# STM32F412VGT7 register map
File version: 1.0
Registers are 32-bit, access not given, reset 0x0 unless marked. A register's access mark holds for its fields unless they carry their own. Offsets are from the block's base; [hi:lo] are bit positions; {n}, {i} and the like mark numbered series.

## GPIOA
Base 0x40020000
Same registers: GPIOB 0x40020400, GPIOC 0x40020800, GPIOD 0x40020C00, GPIOE 0x40021000, GPIOH 0x40021C00
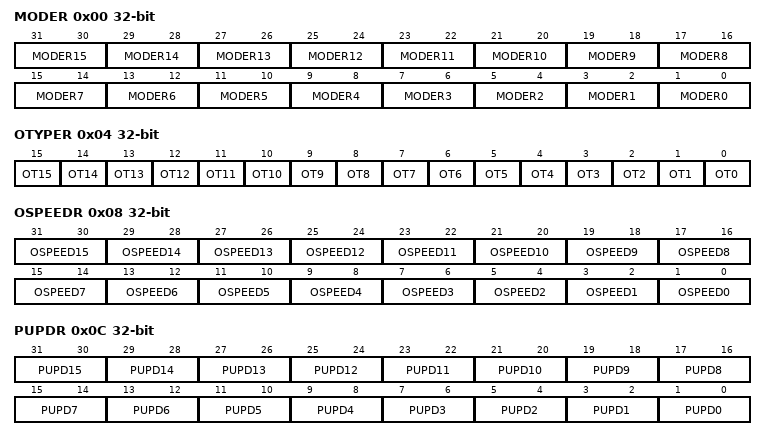
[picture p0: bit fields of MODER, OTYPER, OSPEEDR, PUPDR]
0x00 MODER
  [2n+1:2n] MODER{n} (n=0..15)
0x04 OTYPER
  [n] OT{n} (n=0..15)
0x08 OSPEEDR
  [2n+1:2n] OSPEED{n} (n=0..15)
0x0C PUPDR
  [2n+1:2n] PUPD{n} (n=0..15)
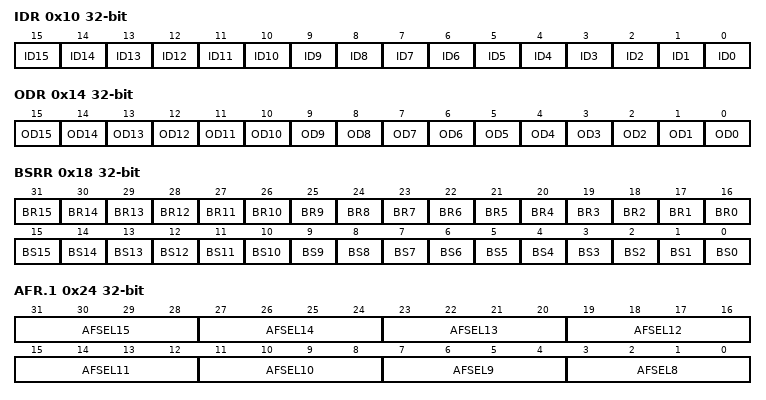
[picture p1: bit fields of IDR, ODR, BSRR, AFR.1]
0x10 IDR
  [n] ID{n} (n=0..15)
0x14 ODR
  [n] OD{n} (n=0..15)
0x18 BSRR
  [n+16] BR{n} (n=0..15), [n] BS{n} (n=0..15)
0x1C LCKR
0x20 AFR.0
0x24 AFR.1
  [4n-29:4n-32] AFSEL{n} (n=8..15)

## CRC
Base 0x40023000
0x00 DR
0x04 IDR 8-bit
0x08 CR
  [0] RESET

## RCC
Base 0x40023800
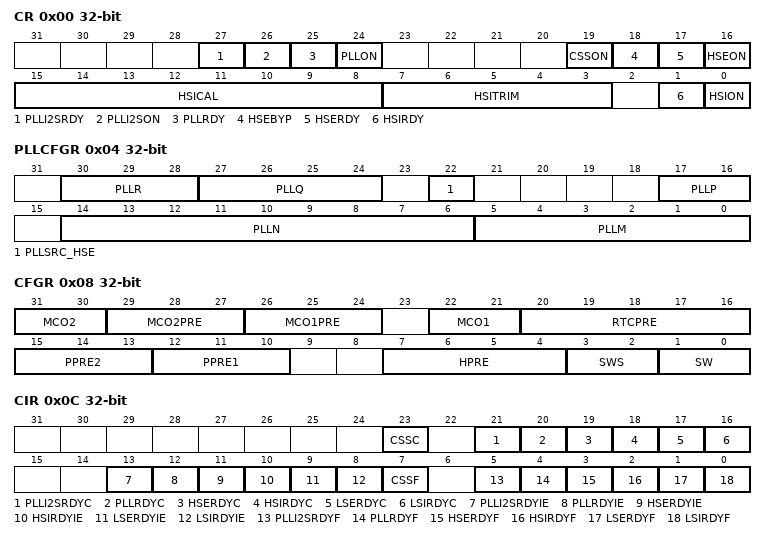
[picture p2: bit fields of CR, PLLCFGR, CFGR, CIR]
0x00 CR
  [27] PLLI2SRDY, [26] PLLI2SON, [25] PLLRDY, [24] PLLON, [19] CSSON, [18] HSEBYP, [17] HSERDY, [16] HSEON, [15:8] HSICAL, [7:3] HSITRIM, [1] HSIRDY, [0] HSION
0x04 PLLCFGR
  [30:28] PLLR, [27:24] PLLQ, [22] PLLSRC_HSE, [17:16] PLLP, [14:6] PLLN, [5:0] PLLM
0x08 CFGR
  [31:30] MCO2, [29:27] MCO2PRE, [26:24] MCO1PRE, [22:21] MCO1, [20:16] RTCPRE, [15:13] PPRE2, [12:10] PPRE1, [7:4] HPRE, [3:2] SWS, [1:0] SW
0x0C CIR
  [23] CSSC, [21] PLLI2SRDYC, [20] PLLRDYC, [19] HSERDYC, [18] HSIRDYC, [17] LSERDYC, [16] LSIRDYC, [13] PLLI2SRDYIE, [12] PLLRDYIE, [11] HSERDYIE, [10] HSIRDYIE, [9] LSERDYIE, [8] LSIRDYIE, [7] CSSF, [5] PLLI2SRDYF, [4] PLLRDYF, [3] HSERDYF, [2] HSIRDYF, [1] LSERDYF, [0] LSIRDYF
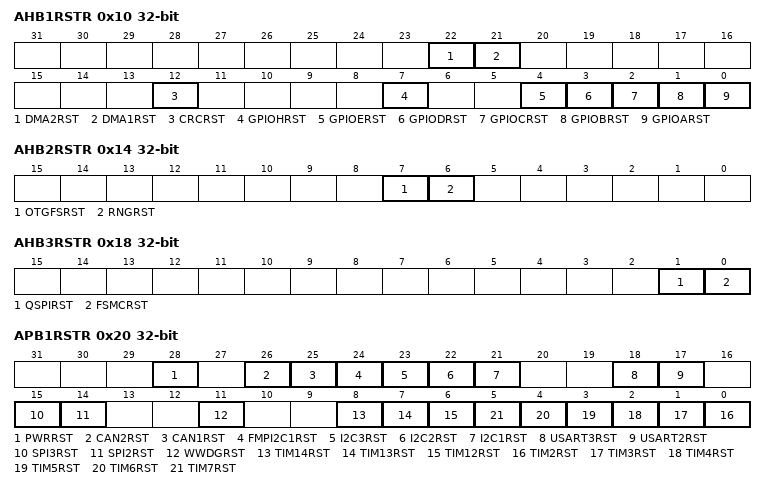
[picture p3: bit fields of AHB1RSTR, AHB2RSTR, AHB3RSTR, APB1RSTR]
0x10 AHB1RSTR
  [22] DMA2RST, [21] DMA1RST, [12] CRCRST, [7] GPIOHRST, [4] GPIOERST, [3] GPIODRST, [2] GPIOCRST, [1] GPIOBRST, [0] GPIOARST
0x14 AHB2RSTR
  [7] OTGFSRST, [6] RNGRST
0x18 AHB3RSTR
  [1] QSPIRST, [0] FSMCRST
0x20 APB1RSTR
  [28] PWRRST, [26] CAN2RST, [25] CAN1RST, [24] FMPI2C1RST, [23] I2C3RST, [22] I2C2RST, [21] I2C1RST, [18] USART3RST, [17] USART2RST, [15] SPI3RST, [14] SPI2RST, [11] WWDGRST, [8] TIM14RST, [7] TIM13RST, [6] TIM12RST, [n-2] TIM{n}RST (n=2..7)
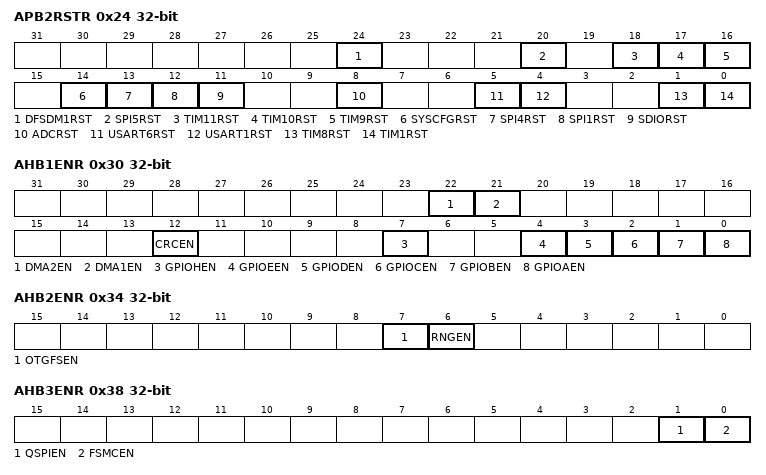
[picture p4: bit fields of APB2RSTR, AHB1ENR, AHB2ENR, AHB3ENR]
0x24 APB2RSTR
  [24] DFSDM1RST, [20] SPI5RST, [18] TIM11RST, [17] TIM10RST, [16] TIM9RST, [14] SYSCFGRST, [13] SPI4RST, [12] SPI1RST, [11] SDIORST, [8] ADCRST, [5] USART6RST, [4] USART1RST, [1] TIM8RST, [0] TIM1RST
0x30 AHB1ENR
  [22] DMA2EN, [21] DMA1EN, [12] CRCEN, [7] GPIOHEN, [4] GPIOEEN, [3] GPIODEN, [2] GPIOCEN, [1] GPIOBEN, [0] GPIOAEN
0x34 AHB2ENR
  [7] OTGFSEN, [6] RNGEN
0x38 AHB3ENR
  [1] QSPIEN, [0] FSMCEN
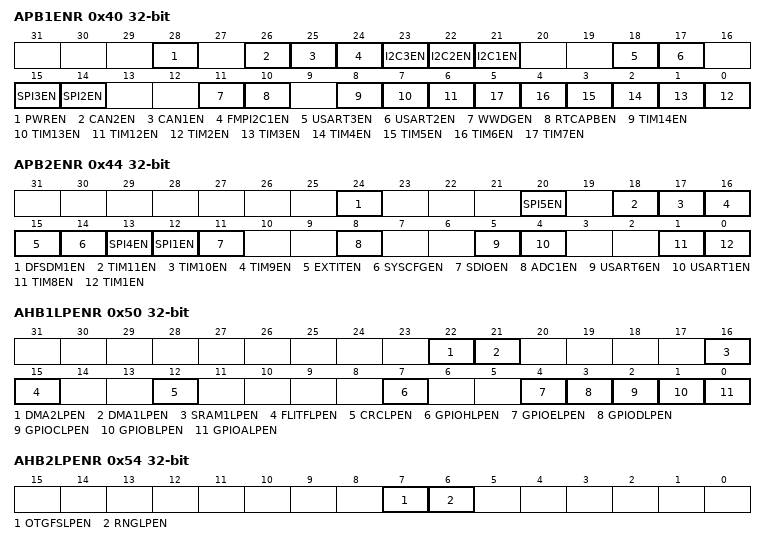
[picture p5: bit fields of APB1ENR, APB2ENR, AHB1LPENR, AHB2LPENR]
0x40 APB1ENR
  [28] PWREN, [26] CAN2EN, [25] CAN1EN, [24] FMPI2C1EN, [23] I2C3EN, [22] I2C2EN, [21] I2C1EN, [18] USART3EN, [17] USART2EN, [15] SPI3EN, [14] SPI2EN, [11] WWDGEN, [10] RTCAPBEN, [8] TIM14EN, [7] TIM13EN, [6] TIM12EN, [n-2] TIM{n}EN (n=2..7)
0x44 APB2ENR
  [24] DFSDM1EN, [20] SPI5EN, [18] TIM11EN, [17] TIM10EN, [16] TIM9EN, [15] EXTITEN, [14] SYSCFGEN, [13] SPI4EN, [12] SPI1EN, [11] SDIOEN, [8] ADC1EN, [5] USART6EN, [4] USART1EN, [1] TIM8EN, [0] TIM1EN
0x50 AHB1LPENR
  [22] DMA2LPEN, [21] DMA1LPEN, [16] SRAM1LPEN, [15] FLITFLPEN, [12] CRCLPEN, [7] GPIOHLPEN, [4] GPIOELPEN, [3] GPIODLPEN, [2] GPIOCLPEN, [1] GPIOBLPEN, [0] GPIOALPEN
0x54 AHB2LPENR
  [7] OTGFSLPEN, [6] RNGLPEN
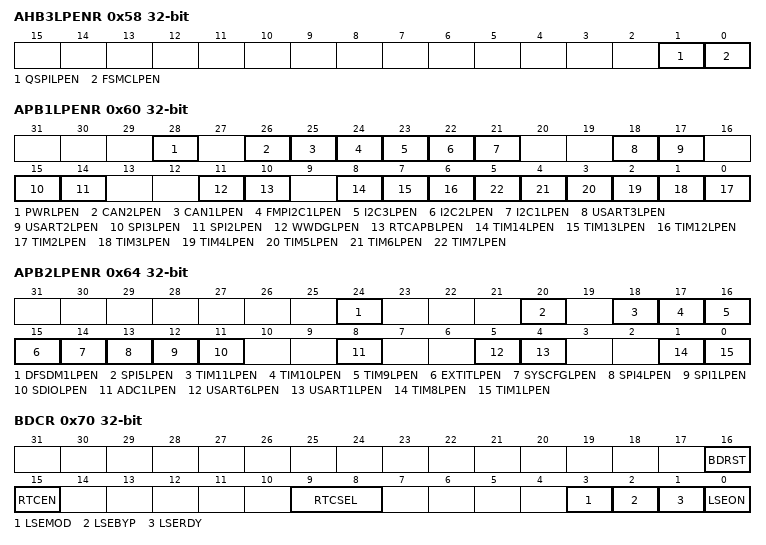
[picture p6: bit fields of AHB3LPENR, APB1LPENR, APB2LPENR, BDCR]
0x58 AHB3LPENR
  [1] QSPILPEN, [0] FSMCLPEN
0x60 APB1LPENR
  [28] PWRLPEN, [26] CAN2LPEN, [25] CAN1LPEN, [24] FMPI2C1LPEN, [23] I2C3LPEN, [22] I2C2LPEN, [21] I2C1LPEN, [18] USART3LPEN, [17] USART2LPEN, [15] SPI3LPEN, [14] SPI2LPEN, [11] WWDGLPEN, [10] RTCAPBLPEN, [8] TIM14LPEN, [7] TIM13LPEN, [6] TIM12LPEN, [n-2] TIM{n}LPEN (n=2..7)
0x64 APB2LPENR
  [24] DFSDM1LPEN, [20] SPI5LPEN, [18] TIM11LPEN, [17] TIM10LPEN, [16] TIM9LPEN, [15] EXTITLPEN, [14] SYSCFGLPEN, [13] SPI4LPEN, [12] SPI1LPEN, [11] SDIOLPEN, [8] ADC1LPEN, [5] USART6LPEN, [4] USART1LPEN, [1] TIM8LPEN, [0] TIM1LPEN
0x70 BDCR
  [16] BDRST, [15] RTCEN, [9:8] RTCSEL, [3] LSEMOD, [2] LSEBYP, [1] LSERDY, [0] LSEON
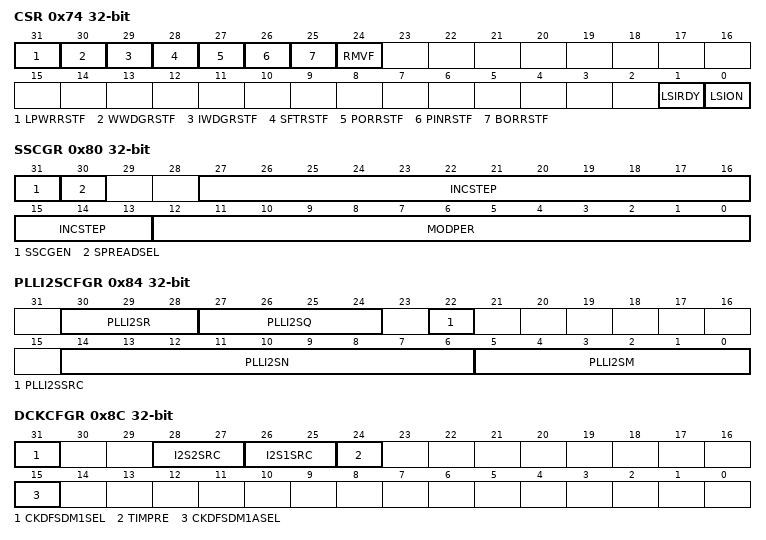
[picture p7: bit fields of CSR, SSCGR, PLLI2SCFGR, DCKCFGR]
0x74 CSR
  [31] LPWRRSTF, [30] WWDGRSTF, [29] IWDGRSTF, [28] SFTRSTF, [27] PORRSTF, [26] PINRSTF, [25] BORRSTF, [24] RMVF, [1] LSIRDY, [0] LSION
0x80 SSCGR
  [31] SSCGEN, [30] SPREADSEL, [27:13] INCSTEP, [12:0] MODPER
0x84 PLLI2SCFGR
  [30:28] PLLI2SR, [27:24] PLLI2SQ, [22] PLLI2SSRC, [14:6] PLLI2SN, [5:0] PLLI2SM
0x8C DCKCFGR
  [31] CKDFSDM1SEL, [28:27] I2S2SRC, [26:25] I2S1SRC, [24] TIMPRE, [15] CKDFSDM1ASEL
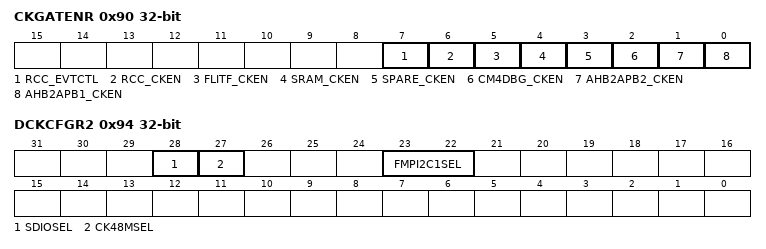
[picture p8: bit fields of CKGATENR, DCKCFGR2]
0x90 CKGATENR
  [7] RCC_EVTCTL, [6] RCC_CKEN, [5] FLITF_CKEN, [4] SRAM_CKEN, [3] SPARE_CKEN, [2] CM4DBG_CKEN, [1] AHB2APB2_CKEN, [0] AHB2APB1_CKEN
0x94 DCKCFGR2
  [28] SDIOSEL, [27] CK48MSEL, [23:22] FMPI2C1SEL
